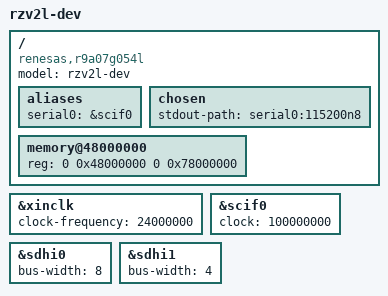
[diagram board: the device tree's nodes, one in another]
// SPDX-License-Identifier: GPL-2.0
/*
 * Device Tree Source for the GR-Peach board
 *
 * Copyright (C) 2017 Jacopo Mondi <jacopo+renesas@jmondi.org>
 * Copyright (C) 2016 Renesas Electronics
 */

/dts-v1/;
#include <dt-bindings/gpio/gpio.h>
#include "r9a07g054l.dtsi"

/ {
	model = "rzv2l-dev";
	compatible = "renesas,r9a07g054l", "renesas,rzv2l";

	aliases {
		serial0 = &scif0;
	};

	chosen {
		stdout-path = "serial0:115200n8";
	};

	memory@48000000 {
		device_type = "memory";
		/* first 128MB is reserved for secure area. */
		reg = <0 0x48000000 0 0x78000000>;
	};

};

&xinclk {
        clock-frequency = <24000000>;
};

&scif0 {
	status = "okay";
	clock = <100000000>;
};

&sdhi0 {
	/* pinctrl placeholder
	 * If this channel is used for interfacing with a SD card, a power enable
	 * pin (SD0_PWR_EN) must be defined.
	 * The SD0_PWR_EN pin is associated with P4_1.
	 * A HIGH signal on SD0_PWR_EN will enable supply voltage for SD card.
	*/
	bus-width = <8>;
	status = "okay";
};

&sdhi1 {
	/* pinctrl placeholder
	 * A power enable pin (SD1_PWR_EN) must be defined to interface with a
	 * SD card.
	 * The SD1_PWR_EN pin is associated with P39_2.
	 * A HIGH signal on SD1_PWR_EN will enable supply voltage for SD card.
	*/
	bus-width = <4>;
	status = "okay";
};
